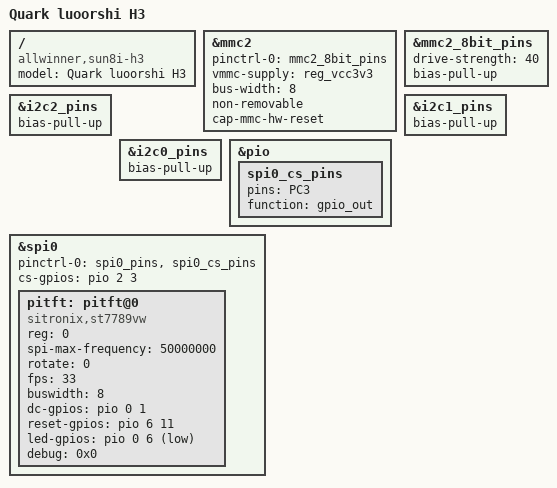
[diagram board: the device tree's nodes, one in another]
/*
 */

#include "sun8i-h3-linux-card.dtsi"

/ {
	model = "Quark luoorshi H3";
	compatible = "luoorshi,Quark-h3", "allwinner,sun8i-h3";

};

&mmc2 {
	pinctrl-names = "default";
	pinctrl-0 = <&mmc2_8bit_pins>;
	vmmc-supply = <&reg_vcc3v3>;
	bus-width = <8>;
	non-removable;
	cap-mmc-hw-reset;
	status = "okay";
};

&mmc2_8bit_pins {
	/* Increase drive strength for DDR modes */
	drive-strength = <40>;
	/* eMMC is missing pull-ups */
	bias-pull-up;
};


&i2c2_pins {
   bias-pull-up;
};

&i2c1_pins {
   bias-pull-up;
};

&i2c0_pins {
   bias-pull-up;
};

/*
 * Device Tree overlay for 1'3 TFT
 */

#include <dt-bindings/gpio/gpio.h>
#include <dt-bindings/interrupt-controller/irq.h>
/ {
	compatible = "allwinner,sun8i-h3";


	fragment@0 {
		target = <&pio>;
		__overlay__ {
			spi0_cs_pins: spi0_cs_pins {
				pins = "PC3";
				function = "gpio_out";
			};
		};
	};

	fragment@1 {
		target = <&spi0>;
		__overlay__ {
			/* needed to avoid dtc warning */
			#address-cells = <1>;
			#size-cells = <0>;
			pinctrl-0 = <&spi0_pins &spi0_cs_pins>;
			cs-gpios = <&pio 2 3 GPIO_ACTIVE_HIGH>;

			pitft: pitft@0{
				compatible = "sitronix,st7789vw";
				reg = <0>;
				status = "okay";

				spi-max-frequency = <50000000>;
				rotate = <0>;
				fps = <33>;
				buswidth = <8>;
				dc-gpios = <&pio 0 1 GPIO_ACTIVE_HIGH>;	 /* PA1 */
				reset-gpios = <&pio 6 11 GPIO_ACTIVE_HIGH>; /* PG11 */
				led-gpios = <&pio 0 6 GPIO_ACTIVE_LOW>;	 /* PA6 */
				debug = <0x0>;
			};
		};
	};
};
